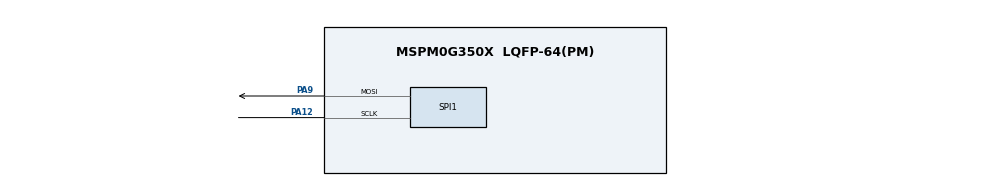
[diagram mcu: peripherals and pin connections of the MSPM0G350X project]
/**
 *
 * @cliArgs --device "MSPM0G350X" --part "Default" --package "LQFP-64(PM)" --product "mspm0_sdk@2.10.00.04"
 * @versions {"tool":"1.28.0+4696"}
 */

/**
 * Import the modules used in this configuration.
 */
const GPIO   = scripting.addModule("/ti/driverlib/GPIO", {}, false);
const GPIO1  = GPIO.addInstance();
const GPIO2  = GPIO.addInstance();
const SPI    = scripting.addModule("/ti/driverlib/SPI", {}, false);
const SPI1   = SPI.addInstance();
const SYSCTL = scripting.addModule("/ti/driverlib/SYSCTL");

/**
 * Write custom configuration values to the imported modules.
 */
GPIO1.$name                         = "GPIO_OLED";
GPIO1.port                          = "PORTB";
GPIO1.associatedPins.create(2);
GPIO1.associatedPins[0].$name       = "DC";
GPIO1.associatedPins[0].assignedPin = "2";
GPIO1.associatedPins[1].$name       = "RES";
GPIO1.associatedPins[1].assignedPin = "3";

const Board = scripting.addModule("/ti/driverlib/Board", {}, false);

GPIO2.$name                              = "GPIO_KEYPAD";
GPIO2.port                               = "PORTB";
GPIO2.associatedPins.create(8);
GPIO2.associatedPins[0].assignedPin      = "16";
GPIO2.associatedPins[0].$name            = "ROW3";
GPIO2.associatedPins[1].assignedPin      = "0";
GPIO2.associatedPins[1].$name            = "ROW2";
GPIO2.associatedPins[2].assignedPin      = "6";
GPIO2.associatedPins[2].$name            = "ROW1";
GPIO2.associatedPins[3].assignedPin      = "8";
GPIO2.associatedPins[3].$name            = "ROW0";
GPIO2.associatedPins[4].$name            = "COL0";
GPIO2.associatedPins[4].assignedPin      = "15";
GPIO2.associatedPins[4].direction        = "INPUT";
GPIO2.associatedPins[4].internalResistor = "PULL_UP";
GPIO2.associatedPins[5].$name            = "COL1";
GPIO2.associatedPins[5].assignedPin      = "17";
GPIO2.associatedPins[5].direction        = "INPUT";
GPIO2.associatedPins[5].internalResistor = "PULL_UP";
GPIO2.associatedPins[6].$name            = "COL2";
GPIO2.associatedPins[6].assignedPin      = "12";
GPIO2.associatedPins[6].direction        = "INPUT";
GPIO2.associatedPins[6].internalResistor = "PULL_UP";
GPIO2.associatedPins[7].$name            = "COL3";
GPIO2.associatedPins[7].assignedPin      = "4";
GPIO2.associatedPins[7].direction        = "INPUT";
GPIO2.associatedPins[7].internalResistor = "PULL_UP";

SPI1.$name                              = "SPI_OLED";
SPI1.chipSelect                         = [];
SPI1.frameFormat                        = "MOTO3";
SPI1.sclkPinConfig.$name                = "ti_driverlib_gpio_GPIOPinGeneric0";
SPI1.sclkPinConfig.direction            = scripting.forceWrite("OUTPUT");
SPI1.sclkPinConfig.onlyInternalResistor = scripting.forceWrite(false);
SPI1.sclkPinConfig.passedPeripheralType = scripting.forceWrite("Digital");
SPI1.mosiPinConfig.$name                = "ti_driverlib_gpio_GPIOPinGeneric1";
SPI1.mosiPinConfig.direction            = scripting.forceWrite("OUTPUT");
SPI1.mosiPinConfig.hideOutputInversion  = scripting.forceWrite(false);
SPI1.mosiPinConfig.onlyInternalResistor = scripting.forceWrite(false);
SPI1.mosiPinConfig.passedPeripheralType = scripting.forceWrite("Digital");
SPI1.misoPinConfig.$name                = "ti_driverlib_gpio_GPIOPinGeneric2";
SPI1.misoPinConfig.onlyInternalResistor = scripting.forceWrite(false);
SPI1.misoPinConfig.passedPeripheralType = scripting.forceWrite("Digital");
SPI1.peripheral.sclkPin.$assign         = "PA12";
SPI1.peripheral.mosiPin.$assign         = "PA9";

SYSCTL.forceDefaultClkConfig = true;

/**
 * Pinmux solution for unlocked pins/peripherals. This ensures that minor changes to the automatic solver in a future
 * version of the tool will not impact the pinmux you originally saw.  These lines can be completely deleted in order to
 * re-solve from scratch.
 */
GPIO1.associatedPins[0].pin.$suggestSolution = "PB2";
GPIO1.associatedPins[1].pin.$suggestSolution = "PB3";
Board.peripheral.$suggestSolution            = "DEBUGSS";
Board.peripheral.swclkPin.$suggestSolution   = "PA20";
Board.peripheral.swdioPin.$suggestSolution   = "PA19";
GPIO2.associatedPins[0].pin.$suggestSolution = "PB16";
GPIO2.associatedPins[1].pin.$suggestSolution = "PB0";
GPIO2.associatedPins[2].pin.$suggestSolution = "PB6";
GPIO2.associatedPins[3].pin.$suggestSolution = "PB8";
GPIO2.associatedPins[4].pin.$suggestSolution = "PB15";
GPIO2.associatedPins[5].pin.$suggestSolution = "PB17";
GPIO2.associatedPins[6].pin.$suggestSolution = "PB12";
GPIO2.associatedPins[7].pin.$suggestSolution = "PB4";
SPI1.peripheral.$suggestSolution             = "SPI0";
SPI1.peripheral.misoPin.$suggestSolution     = "PA10";
SYSCTL.peripheral.$suggestSolution           = "SYSCTL";
